# nrf54ls05b_enga_application register map
Vendor: Nordic Semiconductor; Series: nrf54l; File version: 1
CPU: CM33 r0p4, little endian, no MPU, no FPU, 3 interrupt priority bits, 270 interrupts
Registers are 32-bit, read-write, reset 0x0 unless marked. A register's access mark holds for its fields unless they carry their own. Offsets are from the block's base; [hi:lo] are bit positions; lines under a group give offsets from that group; {n}, {i} and the like mark numbered series.

## GLOBAL_SUPPORT00 — PCGCSlave 0
Base 0x4007F000
Same registers: GLOBAL_SUPPORT10 0x4009E000, GLOBAL_SUPPORT20 0x400FF000, GLOBAL_PCGCS30 0x4011E000, GLOBAL_SUPPORT30 0x4011F000
{0xC00+4i} PENALTY[{i}] (i=0..1) — Description collection: Penalty level for power/clock pair n
  [7:0] PENALTY — Penalty level
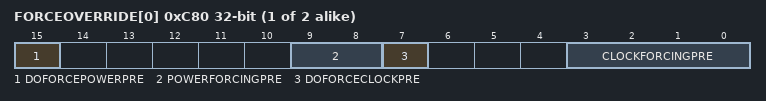
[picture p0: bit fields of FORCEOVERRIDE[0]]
{0xC80+4i} FORCEOVERRIDE[{i}] (i=0..1) — Description collection: Force override of power/clock pair n
  [15] DOFORCEPOWERPRE, [9:8] POWERFORCINGPRE, [7] DOFORCECLOCKPRE, [3:0] CLOCKFORCINGPRE

## GLOBAL_MEMCONF — Memory configuration
Base 0x400CF000
{0x500+0x10*i} POWER[{i}] (i=0..1) group — Unspecified
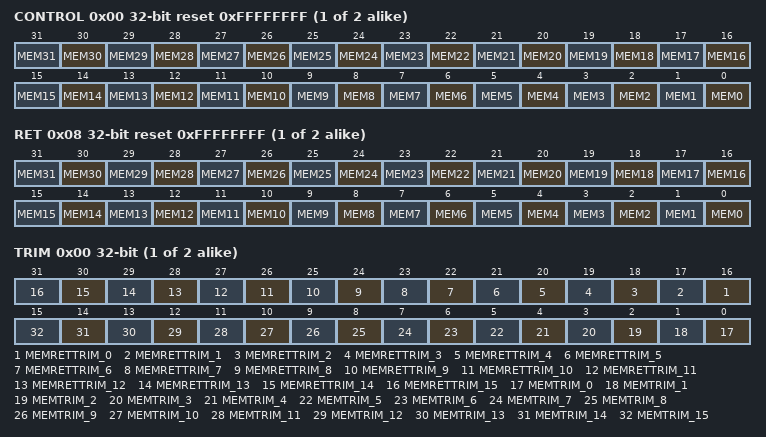
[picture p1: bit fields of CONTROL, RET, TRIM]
  0x00 CONTROL reset 0xFFFFFFFF — Description cluster: Control memory block power.
    [all] fields
      0=Off (Power down); 1=On (Power up)
    [n] MEM{n} (n=0..31) — Keep the memory block MEM[{n}] on or off when in System ON mode.
  0x08 RET reset 0xFFFFFFFF — Description cluster: RAM retention for RAM [n].
    [all] fields
      0=Off (Retention off); 1=On (Retention on)
    [n] MEM{n} (n=0..31) — Keep the RAM block MEM[{n}] retained when in System OFF mode.
{0x900+4i} BLOCKTYPE[{i}] (i=0..1) group — Unspecified
  0x00 TRIM — Description cluster: Trim configuration for the memory block types.
    [n+16] MEMRETTRIM_{n} (n=0..15) — Trimming for retention mode for decreased leakage. Must be kept active in RAM retention mode.
    [n] MEMTRIM_{n} (n=0..15) — Read/write margin trim.

## GLOBAL_P1 — GPIO Port 0
Base 0x400D8200
Same registers: GLOBAL_P0 0x4010A000
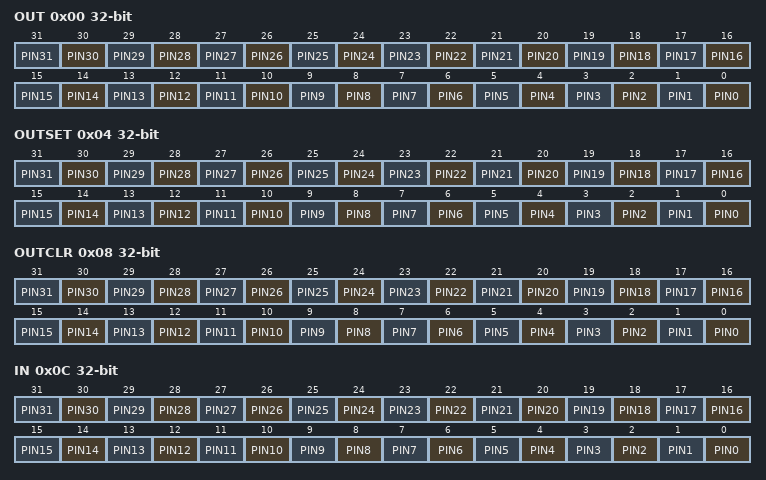
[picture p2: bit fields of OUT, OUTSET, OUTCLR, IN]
0x00 OUT — Write GPIO port
  [all] fields
    0=Low (Pin driver is low); 1=High (Pin driver is high)
  [n] PIN{n} (n=0..31)
0x04 OUTSET write-1-sets — Set individual bits in GPIO port
  [all] fields
    on read: 0=Low (Read: pin driver is low); 1=High (Read: pin driver is high) | on write: 1=Set (Write: writing a '1' sets the pin high; writing a '0' has no effect)
  [n] PIN{n} (n=0..31)
0x08 OUTCLR write-1-clears — Clear individual bits in GPIO port
  [all] fields
    on read: 0=Low (Read: pin driver is low); 1=High (Read: pin driver is high) | on write: 1=Clear (Write: writing a '1' sets the pin low; writing a '0' has no effect)
  [n] PIN{n} (n=0..31)
0x0C IN ro — Read GPIO port
  [all] fields
    0=Low (Pin input is low); 1=High (Pin input is high)
  [n] PIN{n} (n=0..31)
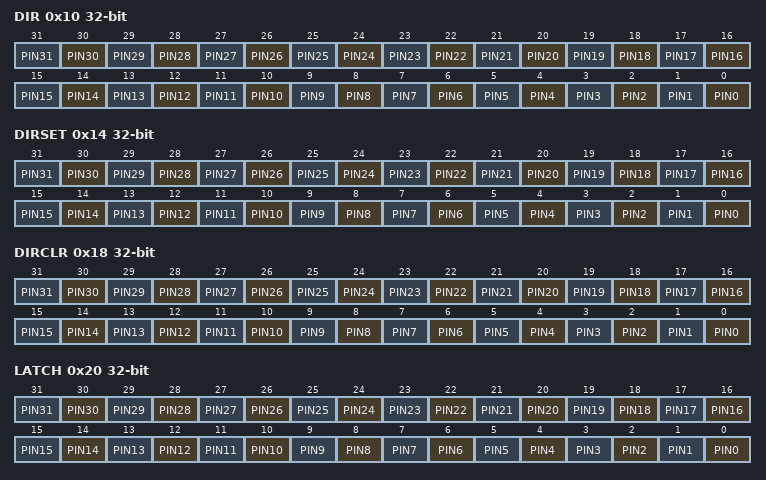
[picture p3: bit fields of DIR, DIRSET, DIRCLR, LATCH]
0x10 DIR — Direction of GPIO pins
  [all] fields
    0=Input (Pin set as input); 1=Output (Pin set as output)
  [n] PIN{n} (n=0..31)
0x14 DIRSET write-1-sets
  [all] fields
    on read: 0=Input (Read: pin set as input); 1=Output (Read: pin set as output) | on write: 1=Set (Write: writing a '1' sets pin to output; writing a '0' has no effect)
  [n] PIN{n} (n=0..31) — Set as output pin {n}
0x18 DIRCLR write-1-clears — DIR clear register
  [all] fields
    on read: 0=Input (Read: pin set as input); 1=Output (Read: pin set as output) | on write: 1=Clear (Write: writing a '1' sets pin to input; writing a '0' has no effect)
  [n] PIN{n} (n=0..31) — Set as input pin {n}
0x20 LATCH — Latch register indicating what GPIO pins that have met the criteria set in the PIN_CNF[n].SENSE registers
  [all] fields
    0=NotLatched (Criteria has not been met); 1=Latched (Criteria has been met)
  [n] PIN{n} (n=0..31) — Status on whether PIN{n} has met criteria set in PIN_CNF[{n}].SENSE register. Write '1' to clear.
0x24 DETECTMODE — Select between default DETECT signal behavior and LDETECT mode
  [0] DETECTMODE
    0=Default (DETECT directly connected to PIN DETECT signals); 1=LDETECT (Use the latched LDETECT behavior)
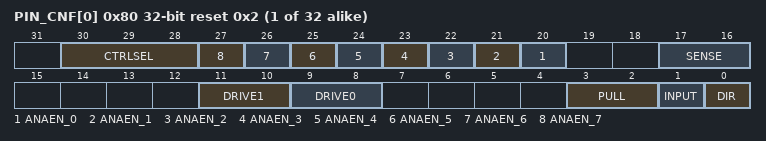
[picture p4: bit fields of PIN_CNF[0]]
{0x80+4i} PIN_CNF[{i}] (i=0..31) reset 0x2 — Description collection: Pin n configuration of GPIO pin
  [30:28] CTRLSEL — Select which module has direct control over this pin
    0=GPIO (GPIO or peripherals with PSEL registers); 1=VPR (VPR processor); 4=GRTC (GRTC peripheral)
  [n+20] ANAEN_{n} (n=0..7) — Control of analog slices for pads with ATB functionality. LSB in ANAEN control slice 0, and so on.
    0=Disabled (Slice disabled); 1=Enabled (Slice enabled)
  [17:16] SENSE — Pin sensing mechanism
    0=Disabled; 2=High (Sense for high level); 3=Low (Sense for low level)
  [11:10] DRIVE1 — Drive configuration for '1'
    0=S1 (Standard '1'); 1=H1 (High drive '1'); 2=D1 (Disconnect '1'(normally used for wired-or connections)); 3=E1 (Extra high drive '1')
  [9:8] DRIVE0 — Drive configuration for '0'
    0=S0 (Standard '0'); 1=H0 (High drive '0'); 2=D0 (Disconnect '0'(normally used for wired-or connections)); 3=E0 (Extra high drive '0')
  [3:2] PULL — Pull configuration
    0=Disabled (No pull); 1=Pull down on pin; 3=Pull up on pin
  [1] INPUT — Connect or disconnect input buffer
    0=Connect input buffer; 1=Disconnect input buffer
  [0] DIR — Pin direction. Same physical register as DIR register
    0=Input (Configure pin as an input pin); 1=Output (Configure pin as an output pin)
